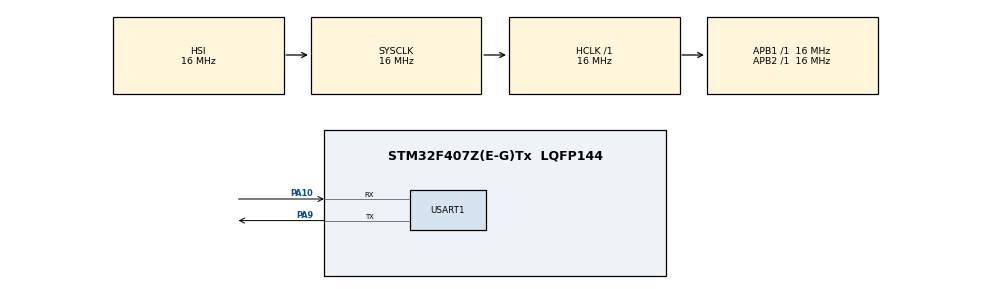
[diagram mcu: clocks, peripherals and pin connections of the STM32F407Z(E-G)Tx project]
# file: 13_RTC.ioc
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Mcu.Family=STM32F4
Mcu.Name=STM32F407Z(E-G)Tx
Mcu.Package=LQFP144
NVIC.PriorityGroup=NVIC_PRIORITYGROUP_4
NVIC.RTC_WKUP_IRQn=true\:0\:0\:false\:false\:true\:true\:true
PA10.Mode=Asynchronous
PA10.Signal=USART1_RX
PA9.Mode=Asynchronous
PA9.Signal=USART1_TX
PC14-OSC32_IN.Mode=LSE-External-Oscillator
PC14-OSC32_IN.Signal=RCC_OSC32_IN
PC15-OSC32_OUT.Mode=LSE-External-Oscillator
PC15-OSC32_OUT.Signal=RCC_OSC32_OUT
ProjectManager.HeapSize=0x200
ProjectManager.StackSize=0x400
ProjectManager.TargetToolchain=MDK-ARM V5
RCC.AHBFreq_Value=16000000
RCC.APB1Freq_Value=16000000
RCC.APB2Freq_Value=16000000
RCC.CortexFreq_Value=16000000
RCC.HSE_VALUE=25000000
RCC.HSI_VALUE=16000000
RCC.RCC_RTC_Clock_Source=RCC_RTCCLKSOURCE_LSE
RCC.SYSCLKFreq_VALUE=16000000
RCC.VCOOutputFreq_Value=192000000
RTC.Format=RTC_FORMAT_BIN
RTC.WakeUpClock=RTC_WAKEUPCLOCK_CK_SPRE_16BITS
USART1.VirtualMode=VM_ASYNC
VP_RTC_VS_RTC_Activate.Mode=RTC_Enabled
VP_RTC_VS_RTC_Calendar.Mode=RTC_Calendar
VP_RTC_VS_RTC_WakeUp_intern.Mode=WakeUp
board=custom

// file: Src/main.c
/* USER CODE BEGIN Header */
/**
  ******************************************************************************
  * @file           : main.c
  * @brief          : Main program body
  ******************************************************************************
  * @attention
  *
  * <h2><center>&copy; Copyright (c) 2019 STMicroelectronics.
  * All rights reserved.</center></h2>
  *
  * This software component is licensed by ST under BSD 3-Clause license,
  * the "License"; You may not use this file except in compliance with the
  * License. You may obtain a copy of the License at:
  *                        opensource.org/licenses/BSD-3-Clause
  *
  ******************************************************************************
  */
/* USER CODE END Header */

#include "main.h"

RTC_HandleTypeDef hrtc;

UART_HandleTypeDef huart1;

void SystemClock_Config(void);
static void MX_GPIO_Init(void);
static void MX_RTC_Init(void);
static void MX_USART1_UART_Init(void);

int main(void)
{
  /* USER CODE BEGIN 1 */
	RTC_DateTypeDef sDate;
	RTC_TimeTypeDef sTime;
	uint8_t second_tmp = 0;
  /* USER CODE END 1 */

  /* MCU Configuration--------------------------------------------------------*/

  /* Reset of all peripherals, Initializes the Flash interface and the Systick. */
  HAL_Init();

  /* Configure the system clock */
  SystemClock_Config();

  /* Initialize all configured peripherals */
  MX_GPIO_Init();
  MX_RTC_Init();
  MX_USART1_UART_Init();

  /* Infinite loop */
  while (1)
  {

    /* USER CODE BEGIN 3 */
	  HAL_Delay(100);
	  HAL_RTC_GetTime(&hrtc, &sTime, RTC_FORMAT_BIN);
	  HAL_RTC_GetDate(&hrtc, &sDate, RTC_FORMAT_BIN);
	  if (second_tmp != sTime.Seconds)
	  {
		  second_tmp = sTime.Seconds;
		  printf("20%d%d-%d%d-%d%d\r\n",
					sDate.Year /10%10, sDate.Year %10,
					sDate.Month /10%10, sDate.Month %10,
					sDate.Date /10%10, sDate.Date %10);
		  printf("%d%d:%d%d:%d%d\r\n\r\n",
					sTime.Hours /10%10, sTime.Hours %10,
					sTime.Minutes /10%10, sTime.Minutes %10,
					sTime.Seconds /10%10, sTime.Seconds %10);
	  }
  }
  /* USER CODE END 3 */
}

void SystemClock_Config(void)
{
  RCC_OscInitTypeDef RCC_OscInitStruct = {0};
  RCC_ClkInitTypeDef RCC_ClkInitStruct = {0};
  RCC_PeriphCLKInitTypeDef PeriphClkInitStruct = {0};

  /** Configure the main internal regulator output voltage
  */
  __HAL_RCC_PWR_CLK_ENABLE();
  __HAL_PWR_VOLTAGESCALING_CONFIG(PWR_REGULATOR_VOLTAGE_SCALE1);
  /** Initializes the CPU, AHB and APB busses clocks
  */
  RCC_OscInitStruct.OscillatorType = RCC_OSCILLATORTYPE_HSI|RCC_OSCILLATORTYPE_LSE;
  RCC_OscInitStruct.LSEState = RCC_LSE_ON;
  RCC_OscInitStruct.HSIState = RCC_HSI_ON;
  RCC_OscInitStruct.HSICalibrationValue = RCC_HSICALIBRATION_DEFAULT;
  RCC_OscInitStruct.PLL.PLLState = RCC_PLL_NONE;
  if (HAL_RCC_OscConfig(&RCC_OscInitStruct) != HAL_OK)
  {
    Error_Handler();
  }
  /** Initializes the CPU, AHB and APB busses clocks
  */
  RCC_ClkInitStruct.ClockType = RCC_CLOCKTYPE_HCLK|RCC_CLOCKTYPE_SYSCLK
                              |RCC_CLOCKTYPE_PCLK1|RCC_CLOCKTYPE_PCLK2;
  RCC_ClkInitStruct.SYSCLKSource = RCC_SYSCLKSOURCE_HSI;
  RCC_ClkInitStruct.AHBCLKDivider = RCC_SYSCLK_DIV1;
  RCC_ClkInitStruct.APB1CLKDivider = RCC_HCLK_DIV1;
  RCC_ClkInitStruct.APB2CLKDivider = RCC_HCLK_DIV1;

  if (HAL_RCC_ClockConfig(&RCC_ClkInitStruct, FLASH_LATENCY_0) != HAL_OK)
  {
    Error_Handler();
  }
  PeriphClkInitStruct.PeriphClockSelection = RCC_PERIPHCLK_RTC;
  PeriphClkInitStruct.RTCClockSelection = RCC_RTCCLKSOURCE_LSE;
  if (HAL_RCCEx_PeriphCLKConfig(&PeriphClkInitStruct) != HAL_OK)
  {
    Error_Handler();
  }
}

static void MX_RTC_Init(void)
{

  RTC_TimeTypeDef sTime = {0};
  RTC_DateTypeDef sDate = {0};

  /** Initialize RTC Only
  */
  hrtc.Instance = RTC;
  hrtc.Init.HourFormat = RTC_HOURFORMAT_24;
  hrtc.Init.AsynchPrediv = 127;
  hrtc.Init.SynchPrediv = 255;
  hrtc.Init.OutPut = RTC_OUTPUT_DISABLE;
  hrtc.Init.OutPutPolarity = RTC_OUTPUT_POLARITY_HIGH;
  hrtc.Init.OutPutType = RTC_OUTPUT_TYPE_OPENDRAIN;
  if (HAL_RTC_Init(&hrtc) != HAL_OK)
  {
    Error_Handler();
  }

  /** Initialize RTC and set the Time and Date
  */
  sTime.Hours = 0;
  sTime.Minutes = 0;
  sTime.Seconds = 0;
  sTime.DayLightSaving = RTC_DAYLIGHTSAVING_NONE;
  sTime.StoreOperation = RTC_STOREOPERATION_RESET;
  if (HAL_RTC_SetTime(&hrtc, &sTime, RTC_FORMAT_BIN) != HAL_OK)
  {
    Error_Handler();
  }
  sDate.WeekDay = RTC_WEEKDAY_MONDAY;
  sDate.Month = RTC_MONTH_JANUARY;
  sDate.Date = 1;
  sDate.Year = 0;

  if (HAL_RTC_SetDate(&hrtc, &sDate, RTC_FORMAT_BIN) != HAL_OK)
  {
    Error_Handler();
  }
  /** Enable the WakeUp
  */
  if (HAL_RTCEx_SetWakeUpTimer_IT(&hrtc, 0, RTC_WAKEUPCLOCK_CK_SPRE_16BITS) != HAL_OK)
  {
    Error_Handler();
  }

}

static void MX_USART1_UART_Init(void)
{

  huart1.Instance = USART1;
  huart1.Init.BaudRate = 115200;
  huart1.Init.WordLength = UART_WORDLENGTH_8B;
  huart1.Init.StopBits = UART_STOPBITS_1;
  huart1.Init.Parity = UART_PARITY_NONE;
  huart1.Init.Mode = UART_MODE_TX_RX;
  huart1.Init.HwFlowCtl = UART_HWCONTROL_NONE;
  huart1.Init.OverSampling = UART_OVERSAMPLING_16;
  if (HAL_UART_Init(&huart1) != HAL_OK)
  {
    Error_Handler();
  }

}

static void MX_GPIO_Init(void)
{

  /* GPIO Ports Clock Enable */
  __HAL_RCC_GPIOC_CLK_ENABLE();
  __HAL_RCC_GPIOA_CLK_ENABLE();

}

/* USER CODE BEGIN 4 */
int fputc(int ch, FILE *f)
{
	HAL_UART_Transmit(&huart1, (uint8_t*)&ch, 1, 10);
	return ch;
}
/* USER CODE END 4 */

void Error_Handler(void)
{
}

/************************ (C) COPYRIGHT STMicroelectronics *****END OF FILE****/
